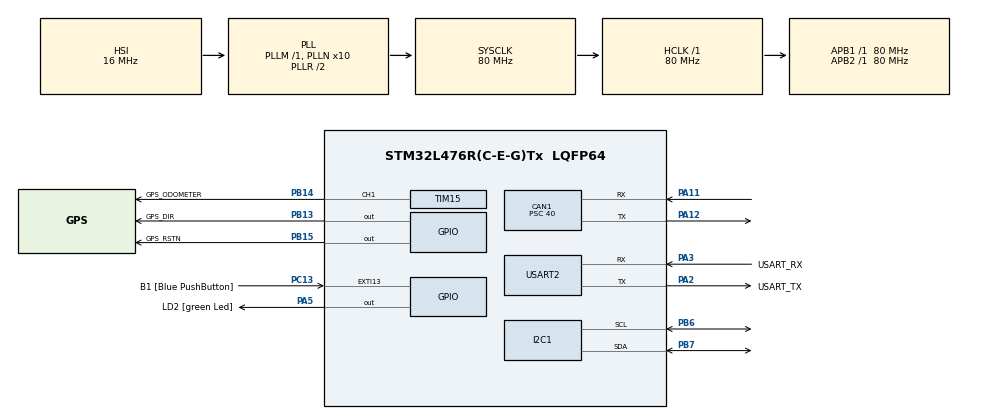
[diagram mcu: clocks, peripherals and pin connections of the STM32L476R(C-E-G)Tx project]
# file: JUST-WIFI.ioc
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CAN1.BS1=CAN_BS1_13TQ
CAN1.BS2=CAN_BS2_2TQ
CAN1.CalculateTimeQuantum=500.0
CAN1.Prescaler=40
Mcu.Family=STM32L4
Mcu.Name=STM32L476R(C-E-G)Tx
Mcu.Package=LQFP64
NVIC.CAN1_RX0_IRQn=true\:0\:0\:false\:false\:true\:true
NVIC.PriorityGroup=NVIC_PRIORITYGROUP_4
PA11.Mode=Master
PA11.Signal=CAN1_RX
PA12.Mode=Master
PA12.Signal=CAN1_TX
PA13\ (JTMS-SWDIO).GPIO_Label=TMS
PA13\ (JTMS-SWDIO).Mode=Serial_Wire
PA13\ (JTMS-SWDIO).Signal=SYS_JTMS-SWDIO
PA14\ (JTCK-SWCLK).GPIO_Label=TCK
PA14\ (JTCK-SWCLK).Mode=Serial_Wire
PA14\ (JTCK-SWCLK).Signal=SYS_JTCK-SWCLK
PA2.GPIO_Label=USART_TX
PA2.GPIO_Mode=GPIO_MODE_AF_PP
PA2.GPIO_PuPd=GPIO_NOPULL
PA2.GPIO_Speed=GPIO_SPEED_FREQ_VERY_HIGH
PA2.Mode=Asynchronous
PA2.Signal=USART2_TX
PA3.GPIO_Label=USART_RX
PA3.GPIO_Mode=GPIO_MODE_AF_PP
PA3.GPIO_PuPd=GPIO_NOPULL
PA3.GPIO_Speed=GPIO_SPEED_FREQ_VERY_HIGH
PA3.Mode=Asynchronous
PA3.Signal=USART2_RX
PA5.GPIO_Label=LD2 [green Led]
PA5.GPIO_ModeDefaultOutputPP=GPIO_MODE_OUTPUT_PP
PA5.GPIO_PuPd=GPIO_NOPULL
PA5.GPIO_Speed=GPIO_SPEED_FREQ_LOW
PA5.Signal=GPIO_Output
PB13.GPIO_Label=GPS_DIR
PB13.GPIO_PuPd=GPIO_PULLDOWN
PB13.Signal=GPIO_Output
PB14.GPIO_Label=GPS_ODOMETER
PB14.Signal=S_TIM15_CH1
PB15.GPIO_Label=GPS_RSTN
PB15.GPIO_PuPd=GPIO_PULLUP
PB15.PinState=GPIO_PIN_SET
PB15.Signal=GPIO_Output
PB3\ (JTDO-TRACESWO).GPIO_Label=SWO
PB3\ (JTDO-TRACESWO).Signal=SYS_JTDO-SWO
PB6.Mode=I2C
PB6.Signal=I2C1_SCL
PB7.Mode=I2C
PB7.Signal=I2C1_SDA
PC13.GPIO_Label=B1 [Blue PushButton]
PC13.GPIO_ModeDefaultEXTI=GPIO_MODE_IT_FALLING
PC13.GPIO_PuPd=GPIO_NOPULL
PC13.Signal=GPXTI13
PC14-OSC32_IN\ (PC14).Mode=LSE-External-Oscillator
PC14-OSC32_IN\ (PC14).Signal=RCC_OSC32_IN
PC15-OSC32_OUT\ (PC15).Mode=LSE-External-Oscillator
PC15-OSC32_OUT\ (PC15).Signal=RCC_OSC32_OUT
PH0-OSC_IN\ (PH0).Signal=RCC_OSC_IN
PH1-OSC_OUT\ (PH1).Signal=RCC_OSC_OUT
ProjectManager.HeapSize=0x200
ProjectManager.StackSize=0x400
ProjectManager.TargetToolchain=TrueSTUDIO
RCC.ADCFreq_Value=64000000
RCC.AHBFreq_Value=80000000
RCC.APB1Freq_Value=80000000
RCC.APB1TimFreq_Value=80000000
RCC.APB2Freq_Value=80000000
RCC.APB2TimFreq_Value=80000000
RCC.CortexFreq_Value=80000000
RCC.HCLKFreq_Value=80000000
RCC.HSE_VALUE=8000000
RCC.HSI_VALUE=16000000
RCC.LSE_VALUE=0.00000000000000000000000000000000000000000000000000000000000000000000000000000000000000000000000000000000003276799999999999
RCC.MSI_VALUE=4000000
RCC.PLLN=10
RCC.PLLSourceVirtual=RCC_PLLSOURCE_HSI
RCC.PREFETCH_ENABLE=1
RCC.SYSCLKFreq_VALUE=80000000
RCC.SYSCLKSource=RCC_SYSCLKSOURCE_PLLCLK
RCC.USBFreq_Value=64000000
RCC.VCOOutputFreq_Value=160000000
SH.S_TIM15_CH1.0=TIM15_CH1,PWM Generation1 CH1
TIM15.Channel-PWM\ Generation1\ CH1=TIM_CHANNEL_1
TIM15.Period=19999
USART2.VirtualMode-Asynchronous=VM_ASYNC
VP_TIM15_VS_ClockSourceINT.Mode=Internal
board=NUCLEO-L476RG

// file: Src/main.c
/* USER CODE BEGIN Header */
/**
 ******************************************************************************
 * @file           : main.c
 * @brief          : Main program body
 ******************************************************************************
 ** This notice applies to any and all portions of this file
 * that are not between comment pairs USER CODE BEGIN and
 * USER CODE END. Other portions of this file, whether
 * inserted by the user or by software development tools
 * are owned by their respective copyright owners.
 *
 * COPYRIGHT(c) 2019 STMicroelectronics
 *
 * Redistribution and use in source and binary forms, with or without modification,
 * are permitted provided that the following conditions are met:
 *   1. Redistributions of source code must retain the above copyright notice,
 *      this list of conditions and the following disclaimer.
 *   2. Redistributions in binary form must reproduce the above copyright notice,
 *      this list of conditions and the following disclaimer in the documentation
 *      and/or other materials provided with the distribution.
 *   3. Neither the name of STMicroelectronics nor the names of its contributors
 *      may be used to endorse or promote products derived from this software
 *      without specific prior written permission.
 *
 * THIS SOFTWARE IS PROVIDED BY THE COPYRIGHT HOLDERS AND CONTRIBUTORS "AS IS"
 * AND ANY EXPRESS OR IMPLIED WARRANTIES, INCLUDING, BUT NOT LIMITED TO, THE
 * IMPLIED WARRANTIES OF MERCHANTABILITY AND FITNESS FOR A PARTICULAR PURPOSE ARE
 * DISCLAIMED. IN NO EVENT SHALL THE COPYRIGHT HOLDER OR CONTRIBUTORS BE LIABLE
 * FOR ANY DIRECT, INDIRECT, INCIDENTAL, SPECIAL, EXEMPLARY, OR CONSEQUENTIAL
 * DAMAGES (INCLUDING, BUT NOT LIMITED TO, PROCUREMENT OF SUBSTITUTE GOODS OR
 * SERVICES; LOSS OF USE, DATA, OR PROFITS; OR BUSINESS INTERRUPTION) HOWEVER
 * CAUSED AND ON ANY THEORY OF LIABILITY, WHETHER IN CONTRACT, STRICT LIABILITY,
 * OR TORT (INCLUDING NEGLIGENCE OR OTHERWISE) ARISING IN ANY WAY OUT OF THE USE
 * OF THIS SOFTWARE, EVEN IF ADVISED OF THE POSSIBILITY OF SUCH DAMAGE.
 *
 ******************************************************************************
 */
/* USER CODE END Header */

#include "main.h"

/* USER CODE BEGIN Includes */
#include "uart.h"
/* USER CODE END Includes */

CAN_HandleTypeDef hcan1;

I2C_HandleTypeDef hi2c1;

TIM_HandleTypeDef htim15;

UART_HandleTypeDef huart2;

/* USER CODE BEGIN PV */
/* Private variables ---------------------------------------------------------*/

/* USER CODE END PV */

void SystemClock_Config(void);
static void MX_GPIO_Init(void);
static void MX_USART2_UART_Init(void);
static void MX_CAN1_Init(void);
static void MX_TIM15_Init(void);
static void MX_I2C1_Init(void);
/* USER CODE BEGIN PFP */
/* Private function prototypes -----------------------------------------------*/

/* USER CODE END PFP */

int main(void)
{

  /* MCU Configuration--------------------------------------------------------*/

  /* Reset of all peripherals, Initializes the Flash interface and the Systick. */
  HAL_Init();

  /* Configure the system clock */
  SystemClock_Config();

  /* Initialize all configured peripherals */
  MX_GPIO_Init();
  MX_USART2_UART_Init();
  MX_CAN1_Init();
  MX_TIM15_Init();
  MX_I2C1_Init();
  /* USER CODE BEGIN 2 */
	debug(ASCII_CLEAR);
	debug(ASCII_HOME);
	debug("Device start\r");
  /* USER CODE END 2 */

  /* Infinite loop */
	while (1)
	{

    /* USER CODE BEGIN 3 */

	}

	return 0;
  /* USER CODE END 3 */
}

void SystemClock_Config(void)
{
  RCC_OscInitTypeDef RCC_OscInitStruct = {0};
  RCC_ClkInitTypeDef RCC_ClkInitStruct = {0};
  RCC_PeriphCLKInitTypeDef PeriphClkInit = {0};

  /**Initializes the CPU, AHB and APB busses clocks
  */
  RCC_OscInitStruct.OscillatorType = RCC_OSCILLATORTYPE_HSI;
  RCC_OscInitStruct.HSIState = RCC_HSI_ON;
  RCC_OscInitStruct.HSICalibrationValue = RCC_HSICALIBRATION_DEFAULT;
  RCC_OscInitStruct.PLL.PLLState = RCC_PLL_ON;
  RCC_OscInitStruct.PLL.PLLSource = RCC_PLLSOURCE_HSI;
  RCC_OscInitStruct.PLL.PLLM = 1;
  RCC_OscInitStruct.PLL.PLLN = 10;
  RCC_OscInitStruct.PLL.PLLP = RCC_PLLP_DIV7;
  RCC_OscInitStruct.PLL.PLLQ = RCC_PLLQ_DIV2;
  RCC_OscInitStruct.PLL.PLLR = RCC_PLLR_DIV2;
  if (HAL_RCC_OscConfig(&RCC_OscInitStruct) != HAL_OK)
  {
    Error_Handler();
  }
  /**Initializes the CPU, AHB and APB busses clocks
  */
  RCC_ClkInitStruct.ClockType = RCC_CLOCKTYPE_HCLK|RCC_CLOCKTYPE_SYSCLK
                              |RCC_CLOCKTYPE_PCLK1|RCC_CLOCKTYPE_PCLK2;
  RCC_ClkInitStruct.SYSCLKSource = RCC_SYSCLKSOURCE_PLLCLK;
  RCC_ClkInitStruct.AHBCLKDivider = RCC_SYSCLK_DIV1;
  RCC_ClkInitStruct.APB1CLKDivider = RCC_HCLK_DIV1;
  RCC_ClkInitStruct.APB2CLKDivider = RCC_HCLK_DIV1;

  if (HAL_RCC_ClockConfig(&RCC_ClkInitStruct, FLASH_LATENCY_4) != HAL_OK)
  {
    Error_Handler();
  }
  PeriphClkInit.PeriphClockSelection = RCC_PERIPHCLK_USART2|RCC_PERIPHCLK_I2C1;
  PeriphClkInit.Usart2ClockSelection = RCC_USART2CLKSOURCE_PCLK1;
  PeriphClkInit.I2c1ClockSelection = RCC_I2C1CLKSOURCE_PCLK1;
  if (HAL_RCCEx_PeriphCLKConfig(&PeriphClkInit) != HAL_OK)
  {
    Error_Handler();
  }
  /**Configure the main internal regulator output voltage
  */
  if (HAL_PWREx_ControlVoltageScaling(PWR_REGULATOR_VOLTAGE_SCALE1) != HAL_OK)
  {
    Error_Handler();
  }
}

static void MX_CAN1_Init(void)
{

  hcan1.Instance = CAN1;
  hcan1.Init.Prescaler = 40;
  hcan1.Init.Mode = CAN_MODE_NORMAL;
  hcan1.Init.SyncJumpWidth = CAN_SJW_1TQ;
  hcan1.Init.TimeSeg1 = CAN_BS1_13TQ;
  hcan1.Init.TimeSeg2 = CAN_BS2_2TQ;
  hcan1.Init.TimeTriggeredMode = DISABLE;
  hcan1.Init.AutoBusOff = DISABLE;
  hcan1.Init.AutoWakeUp = DISABLE;
  hcan1.Init.AutoRetransmission = DISABLE;
  hcan1.Init.ReceiveFifoLocked = DISABLE;
  hcan1.Init.TransmitFifoPriority = DISABLE;
  if (HAL_CAN_Init(&hcan1) != HAL_OK)
  {
    Error_Handler();
  }

}

static void MX_I2C1_Init(void)
{

  hi2c1.Instance = I2C1;
  hi2c1.Init.Timing = 0x10909CEC;
  hi2c1.Init.OwnAddress1 = 0;
  hi2c1.Init.AddressingMode = I2C_ADDRESSINGMODE_7BIT;
  hi2c1.Init.DualAddressMode = I2C_DUALADDRESS_DISABLE;
  hi2c1.Init.OwnAddress2 = 0;
  hi2c1.Init.OwnAddress2Masks = I2C_OA2_NOMASK;
  hi2c1.Init.GeneralCallMode = I2C_GENERALCALL_DISABLE;
  hi2c1.Init.NoStretchMode = I2C_NOSTRETCH_DISABLE;
  if (HAL_I2C_Init(&hi2c1) != HAL_OK)
  {
    Error_Handler();
  }
  /**Configure Analogue filter
  */
  if (HAL_I2CEx_ConfigAnalogFilter(&hi2c1, I2C_ANALOGFILTER_ENABLE) != HAL_OK)
  {
    Error_Handler();
  }
  /**Configure Digital filter
  */
  if (HAL_I2CEx_ConfigDigitalFilter(&hi2c1, 0) != HAL_OK)
  {
    Error_Handler();
  }

}

static void MX_TIM15_Init(void)
{

  TIM_ClockConfigTypeDef sClockSourceConfig = {0};
  TIM_MasterConfigTypeDef sMasterConfig = {0};
  TIM_OC_InitTypeDef sConfigOC = {0};
  TIM_BreakDeadTimeConfigTypeDef sBreakDeadTimeConfig = {0};

  htim15.Instance = TIM15;
  htim15.Init.Prescaler = 0;
  htim15.Init.CounterMode = TIM_COUNTERMODE_UP;
  htim15.Init.Period = 19999;
  htim15.Init.ClockDivision = TIM_CLOCKDIVISION_DIV1;
  htim15.Init.RepetitionCounter = 0;
  htim15.Init.AutoReloadPreload = TIM_AUTORELOAD_PRELOAD_DISABLE;
  if (HAL_TIM_Base_Init(&htim15) != HAL_OK)
  {
    Error_Handler();
  }
  sClockSourceConfig.ClockSource = TIM_CLOCKSOURCE_INTERNAL;
  if (HAL_TIM_ConfigClockSource(&htim15, &sClockSourceConfig) != HAL_OK)
  {
    Error_Handler();
  }
  if (HAL_TIM_PWM_Init(&htim15) != HAL_OK)
  {
    Error_Handler();
  }
  sMasterConfig.MasterOutputTrigger = TIM_TRGO_RESET;
  sMasterConfig.MasterSlaveMode = TIM_MASTERSLAVEMODE_DISABLE;
  if (HAL_TIMEx_MasterConfigSynchronization(&htim15, &sMasterConfig) != HAL_OK)
  {
    Error_Handler();
  }
  sConfigOC.OCMode = TIM_OCMODE_PWM1;
  sConfigOC.Pulse = 0;
  sConfigOC.OCPolarity = TIM_OCPOLARITY_HIGH;
  sConfigOC.OCNPolarity = TIM_OCNPOLARITY_HIGH;
  sConfigOC.OCFastMode = TIM_OCFAST_DISABLE;
  sConfigOC.OCIdleState = TIM_OCIDLESTATE_RESET;
  sConfigOC.OCNIdleState = TIM_OCNIDLESTATE_RESET;
  if (HAL_TIM_PWM_ConfigChannel(&htim15, &sConfigOC, TIM_CHANNEL_1) != HAL_OK)
  {
    Error_Handler();
  }
  sBreakDeadTimeConfig.OffStateRunMode = TIM_OSSR_DISABLE;
  sBreakDeadTimeConfig.OffStateIDLEMode = TIM_OSSI_DISABLE;
  sBreakDeadTimeConfig.LockLevel = TIM_LOCKLEVEL_OFF;
  sBreakDeadTimeConfig.DeadTime = 0;
  sBreakDeadTimeConfig.BreakState = TIM_BREAK_DISABLE;
  sBreakDeadTimeConfig.BreakPolarity = TIM_BREAKPOLARITY_HIGH;
  sBreakDeadTimeConfig.BreakFilter = 0;
  sBreakDeadTimeConfig.AutomaticOutput = TIM_AUTOMATICOUTPUT_DISABLE;
  if (HAL_TIMEx_ConfigBreakDeadTime(&htim15, &sBreakDeadTimeConfig) != HAL_OK)
  {
    Error_Handler();
  }
  HAL_TIM_MspPostInit(&htim15);

}

static void MX_USART2_UART_Init(void)
{

  huart2.Instance = USART2;
  huart2.Init.BaudRate = 115200;
  huart2.Init.WordLength = UART_WORDLENGTH_8B;
  huart2.Init.StopBits = UART_STOPBITS_1;
  huart2.Init.Parity = UART_PARITY_NONE;
  huart2.Init.Mode = UART_MODE_TX_RX;
  huart2.Init.HwFlowCtl = UART_HWCONTROL_NONE;
  huart2.Init.OverSampling = UART_OVERSAMPLING_16;
  huart2.Init.OneBitSampling = UART_ONE_BIT_SAMPLE_DISABLE;
  huart2.AdvancedInit.AdvFeatureInit = UART_ADVFEATURE_NO_INIT;
  if (HAL_UART_Init(&huart2) != HAL_OK)
  {
    Error_Handler();
  }

}

static void MX_GPIO_Init(void)
{
  GPIO_InitTypeDef GPIO_InitStruct = {0};

  /* GPIO Ports Clock Enable */
  __HAL_RCC_GPIOC_CLK_ENABLE();
  __HAL_RCC_GPIOH_CLK_ENABLE();
  __HAL_RCC_GPIOA_CLK_ENABLE();
  __HAL_RCC_GPIOB_CLK_ENABLE();

  /*Configure GPIO pin Output Level */
  HAL_GPIO_WritePin(LD2_GPIO_Port, LD2_Pin, GPIO_PIN_RESET);

  /*Configure GPIO pin Output Level */
  HAL_GPIO_WritePin(GPS_DIR_GPIO_Port, GPS_DIR_Pin, GPIO_PIN_RESET);

  /*Configure GPIO pin Output Level */
  HAL_GPIO_WritePin(GPS_RSTN_GPIO_Port, GPS_RSTN_Pin, GPIO_PIN_SET);

  /*Configure GPIO pin : B1_Pin */
  GPIO_InitStruct.Pin = B1_Pin;
  GPIO_InitStruct.Mode = GPIO_MODE_IT_FALLING;
  GPIO_InitStruct.Pull = GPIO_NOPULL;
  HAL_GPIO_Init(B1_GPIO_Port, &GPIO_InitStruct);

  /*Configure GPIO pin : LD2_Pin */
  GPIO_InitStruct.Pin = LD2_Pin;
  GPIO_InitStruct.Mode = GPIO_MODE_OUTPUT_PP;
  GPIO_InitStruct.Pull = GPIO_NOPULL;
  GPIO_InitStruct.Speed = GPIO_SPEED_FREQ_LOW;
  HAL_GPIO_Init(LD2_GPIO_Port, &GPIO_InitStruct);

  /*Configure GPIO pin : GPS_DIR_Pin */
  GPIO_InitStruct.Pin = GPS_DIR_Pin;
  GPIO_InitStruct.Mode = GPIO_MODE_OUTPUT_PP;
  GPIO_InitStruct.Pull = GPIO_PULLDOWN;
  GPIO_InitStruct.Speed = GPIO_SPEED_FREQ_LOW;
  HAL_GPIO_Init(GPS_DIR_GPIO_Port, &GPIO_InitStruct);

  /*Configure GPIO pin : GPS_RSTN_Pin */
  GPIO_InitStruct.Pin = GPS_RSTN_Pin;
  GPIO_InitStruct.Mode = GPIO_MODE_OUTPUT_PP;
  GPIO_InitStruct.Pull = GPIO_PULLUP;
  GPIO_InitStruct.Speed = GPIO_SPEED_FREQ_LOW;
  HAL_GPIO_Init(GPS_RSTN_GPIO_Port, &GPIO_InitStruct);

}

void Error_Handler(void)
{
	while(1)
	{
	}
}

/************************ (C) COPYRIGHT STMicroelectronics *****END OF FILE****/
